VERSION "1.0"
NS_ :

BS_:
BU_: SensorManager ActuatorUnit Gateway

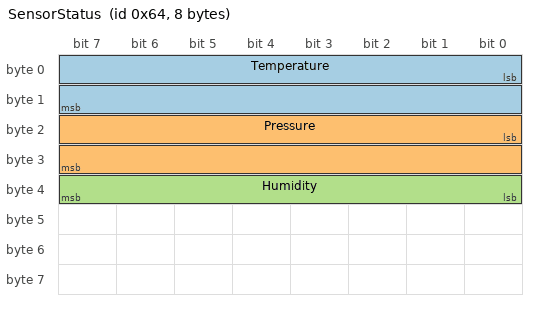
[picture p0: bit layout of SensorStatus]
BO_ 100 SensorStatus: 8 SensorManager
 SG_ Temperature : 0|16@1+ (0.1,0) [0|150] "C"  SensorManager
 SG_ Pressure : 16|16@1+ (0.01,0) [0|10] "Bar"  SensorManager
 SG_ Humidity : 32|8@1+ (0.5,0) [0|100] "%"  SensorManager

BO_ 200 ControlCommand: 4 Gateway
 SG_ CommandID : 0|8@1+ (1,0) [0|255] ""  Gateway
 SG_ Value : 8|8@1+ (1,0) [0|255] ""  Gateway

BO_ 300 ActuatorFeedback: 8 ActuatorUnit
 SG_ MotorSpeed : 0|16@1+ (0.25,0) [0|8000] "RPM"  ActuatorUnit
 SG_ Torque : 16|16@1+ (0.1,0) [0|500] "Nm"  ActuatorUnit

CM_ "Simple CAN database template";
BA_DEF_  "BusType" STRING ;
BA_ "BusType" "CAN";

VAL_  CommandID  1 "START"  2 "STOP"  3 "RESET"  4 "CALIBRATE" ;
